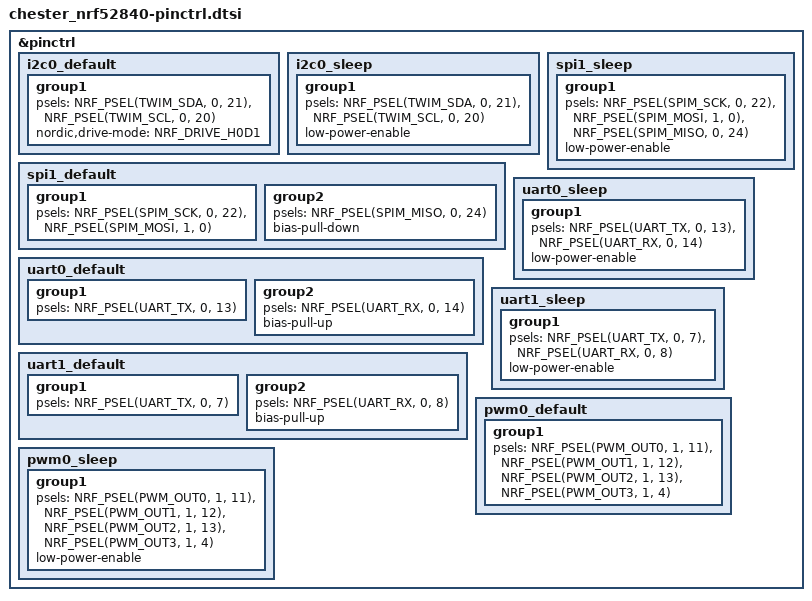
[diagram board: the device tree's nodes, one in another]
/*
 * Copyright (c) 2023 HARDWARIO a.s.
 *
 * SPDX-License-Identifier: LicenseRef-HARDWARIO-5-Clause
 */

&pinctrl {
	i2c0_default: i2c0_default {
		group1 {
			psels = <NRF_PSEL(TWIM_SDA, 0, 21)>,
			        <NRF_PSEL(TWIM_SCL, 0, 20)>;
			nordic,drive-mode = <NRF_DRIVE_H0D1>;
		};
	};

	i2c0_sleep: i2c0_sleep {
		group1 {
			psels = <NRF_PSEL(TWIM_SDA, 0, 21)>,
			        <NRF_PSEL(TWIM_SCL, 0, 20)>;
			low-power-enable;
		};
	};

	spi1_default: spi1_default {
		group1 {
			psels = <NRF_PSEL(SPIM_SCK, 0, 22)>,
			        <NRF_PSEL(SPIM_MOSI, 1, 0)>;
		};
		group2 {
			psels = <NRF_PSEL(SPIM_MISO, 0, 24)>;
			bias-pull-down;
		};
	};

	spi1_sleep: spi1_sleep {
		group1 {
			psels = <NRF_PSEL(SPIM_SCK, 0, 22)>,
			        <NRF_PSEL(SPIM_MOSI, 1, 0)>,
			        <NRF_PSEL(SPIM_MISO, 0, 24)>;
			low-power-enable;
		};
	};

	uart0_default: uart0_default {
		group1 {
			psels = <NRF_PSEL(UART_TX, 0, 13)>;
		};
		group2 {
			psels = <NRF_PSEL(UART_RX, 0, 14)>;
			bias-pull-up;
		};
	};

	uart0_sleep: uart0_sleep {
		group1 {
			psels = <NRF_PSEL(UART_TX, 0, 13)>,
			        <NRF_PSEL(UART_RX, 0, 14)>;
			low-power-enable;
		};
	};

	uart1_default: uart1_default {
		group1 {
			psels = <NRF_PSEL(UART_TX, 0, 7)>;
		};
		group2 {
			psels = <NRF_PSEL(UART_RX, 0, 8)>;
			bias-pull-up;
		};
	};

	uart1_sleep: uart1_sleep {
		group1 {
			psels = <NRF_PSEL(UART_TX, 0, 7)>,
			        <NRF_PSEL(UART_RX, 0, 8)>;
			low-power-enable;
		};
	};

	pwm0_default: pwm0_default {
		group1 {
			psels = <NRF_PSEL(PWM_OUT0, 1, 11)>,
			        <NRF_PSEL(PWM_OUT1, 1, 12)>,
			        <NRF_PSEL(PWM_OUT2, 1, 13)>,
			        <NRF_PSEL(PWM_OUT3, 1, 4)>;
		};
	};

	pwm0_sleep: pwm0_sleep {
		group1 {
			psels = <NRF_PSEL(PWM_OUT0, 1, 11)>,
			        <NRF_PSEL(PWM_OUT1, 1, 12)>,
			        <NRF_PSEL(PWM_OUT2, 1, 13)>,
			        <NRF_PSEL(PWM_OUT3, 1, 4)>;
			low-power-enable;
		};
	};
};
